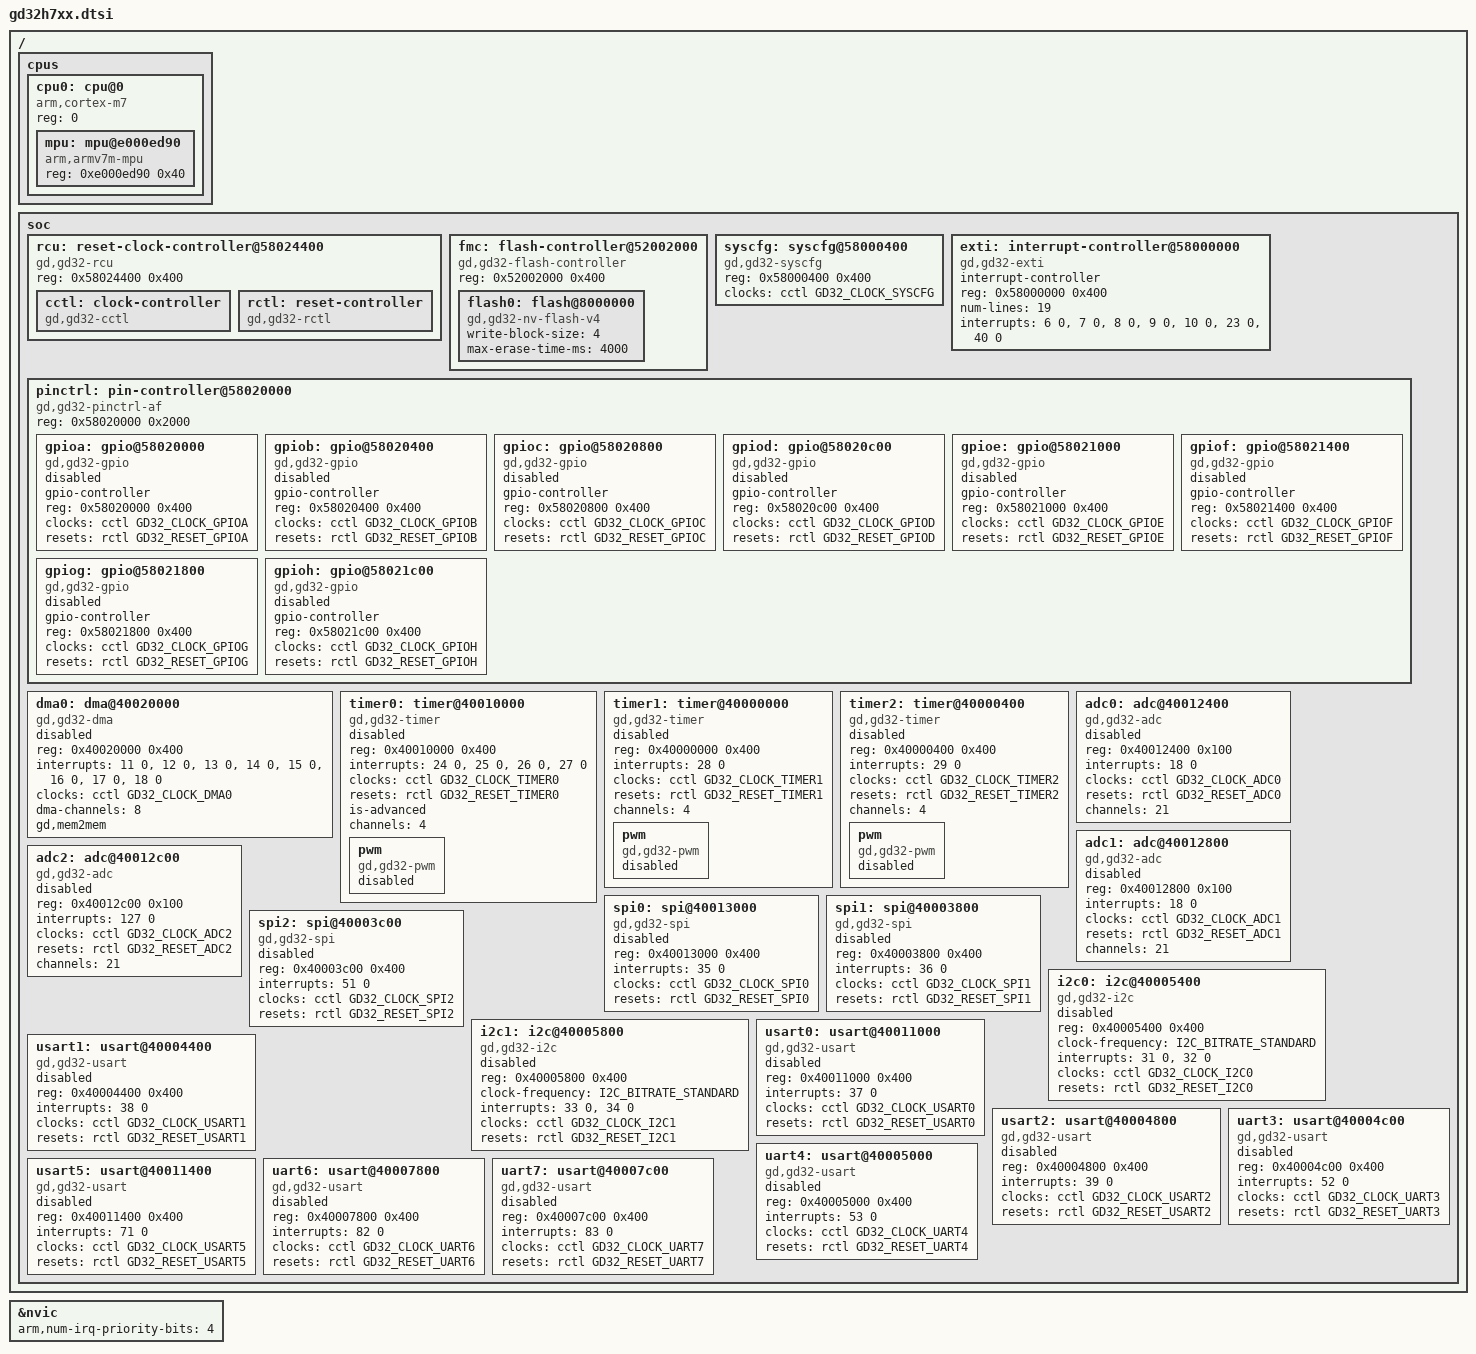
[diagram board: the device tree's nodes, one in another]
/*
 * Copyright (c) 2026 GD32H7xx Zephyr bring-up
 * SPDX-License-Identifier: Apache-2.0
 */

#include <arm/armv7-m.dtsi>
#include <zephyr/dt-bindings/gpio/gpio.h>
#include <zephyr/dt-bindings/i2c/i2c.h>
#include <zephyr/dt-bindings/clock/gd32h7xx-clocks.h>
#include <zephyr/dt-bindings/reset/gd32h7xx.h>

&nvic {
	arm,num-irq-priority-bits = <4>;
};

/ {
	cpus {
		#address-cells = <1>;
		#size-cells = <0>;

		cpu0: cpu@0 {
			compatible = "arm,cortex-m7";
			reg = <0>;
			#address-cells = <1>;
			#size-cells = <1>;

			mpu: mpu@e000ed90 {
				compatible = "arm,armv7m-mpu";
				reg = <0xe000ed90 0x40>;
			};
		};
	};

	soc {
		rcu: reset-clock-controller@58024400 {
			compatible = "gd,gd32-rcu";
			reg = <0x58024400 0x400>;
			status = "okay";

			cctl: clock-controller {
				compatible = "gd,gd32-cctl";
				#clock-cells = <1>;
				status = "okay";
			};

			rctl: reset-controller {
				compatible = "gd,gd32-rctl";
				#reset-cells = <1>;
				status = "okay";
			};
		};

		fmc: flash-controller@52002000 {
			compatible = "gd,gd32-flash-controller";
			reg = <0x52002000 0x400>;

			#address-cells = <1>;
			#size-cells = <1>;

			flash0: flash@8000000 {
				compatible = "gd,gd32-nv-flash-v4", "soc-nv-flash";
				write-block-size = <4>;
				max-erase-time-ms = <4000>;
			};
		};

		syscfg: syscfg@58000400 {
			compatible = "gd,gd32-syscfg";
			reg = <0x58000400 0x400>;
			clocks = <&cctl GD32_CLOCK_SYSCFG>;
			status = "okay";
		};

		exti: interrupt-controller@58000000 {
			compatible = "gd,gd32-exti";
			interrupt-controller;
			#interrupt-cells = <1>;
			reg = <0x58000000 0x400>;
			num-lines = <19>;
			interrupts = <6 0>, <7 0>, <8 0>, <9 0>, <10 0>, <23 0>,
				     <40 0>;
			interrupt-names = "line0", "line1", "line2", "line3",
					  "line4", "line5-9", "line10-15";
			status = "okay";
		};

		pinctrl: pin-controller@58020000 {
			compatible = "gd,gd32-pinctrl-af";
			reg = <0x58020000 0x2000>;
			#address-cells = <1>;
			#size-cells = <1>;
			status = "okay";

			gpioa: gpio@58020000 {
				compatible = "gd,gd32-gpio";
				gpio-controller;
				#gpio-cells = <2>;
				reg = <0x58020000 0x400>;
				clocks = <&cctl GD32_CLOCK_GPIOA>;
				resets = <&rctl GD32_RESET_GPIOA>;
				status = "disabled";
			};

			gpiob: gpio@58020400 {
				compatible = "gd,gd32-gpio";
				gpio-controller;
				#gpio-cells = <2>;
				reg = <0x58020400 0x400>;
				clocks = <&cctl GD32_CLOCK_GPIOB>;
				resets = <&rctl GD32_RESET_GPIOB>;
				status = "disabled";
			};

			gpioc: gpio@58020800 {
				compatible = "gd,gd32-gpio";
				gpio-controller;
				#gpio-cells = <2>;
				reg = <0x58020800 0x400>;
				clocks = <&cctl GD32_CLOCK_GPIOC>;
				resets = <&rctl GD32_RESET_GPIOC>;
				status = "disabled";
			};

			gpiod: gpio@58020c00 {
				compatible = "gd,gd32-gpio";
				gpio-controller;
				#gpio-cells = <2>;
				reg = <0x58020c00 0x400>;
				clocks = <&cctl GD32_CLOCK_GPIOD>;
				resets = <&rctl GD32_RESET_GPIOD>;
				status = "disabled";
			};

			gpioe: gpio@58021000 {
				compatible = "gd,gd32-gpio";
				gpio-controller;
				#gpio-cells = <2>;
				reg = <0x58021000 0x400>;
				clocks = <&cctl GD32_CLOCK_GPIOE>;
				resets = <&rctl GD32_RESET_GPIOE>;
				status = "disabled";
			};

			gpiof: gpio@58021400 {
				compatible = "gd,gd32-gpio";
				gpio-controller;
				#gpio-cells = <2>;
				reg = <0x58021400 0x400>;
				clocks = <&cctl GD32_CLOCK_GPIOF>;
				resets = <&rctl GD32_RESET_GPIOF>;
				status = "disabled";
			};

			gpiog: gpio@58021800 {
				compatible = "gd,gd32-gpio";
				gpio-controller;
				#gpio-cells = <2>;
				reg = <0x58021800 0x400>;
				clocks = <&cctl GD32_CLOCK_GPIOG>;
				resets = <&rctl GD32_RESET_GPIOG>;
				status = "disabled";
			};

			gpioh: gpio@58021c00 {
				compatible = "gd,gd32-gpio";
				gpio-controller;
				#gpio-cells = <2>;
				reg = <0x58021c00 0x400>;
				clocks = <&cctl GD32_CLOCK_GPIOH>;
				resets = <&rctl GD32_RESET_GPIOH>;
				status = "disabled";
			};
		};

		dma0: dma@40020000 {
			compatible = "gd,gd32-dma";
			reg = <0x40020000 0x400>;
			interrupts = <11 0>, <12 0>, <13 0>, <14 0>,
				     <15 0>, <16 0>, <17 0>, <18 0>;
			clocks = <&cctl GD32_CLOCK_DMA0>;
			dma-channels = <8>;
			gd,mem2mem;
			#dma-cells = <2>;
			status = "disabled";
		};

		timer0: timer@40010000 {
			compatible = "gd,gd32-timer";
			reg = <0x40010000 0x400>;
			interrupts = <24 0>, <25 0>, <26 0>, <27 0>;
			interrupt-names = "brk", "up", "trgcom", "cc";
			clocks = <&cctl GD32_CLOCK_TIMER0>;
			resets = <&rctl GD32_RESET_TIMER0>;
			is-advanced;
			channels = <4>;
			status = "disabled";

			pwm {
				compatible = "gd,gd32-pwm";
				status = "disabled";
				#pwm-cells = <3>;
			};
		};

		timer1: timer@40000000 {
			compatible = "gd,gd32-timer";
			reg = <0x40000000 0x400>;
			interrupts = <28 0>;
			interrupt-names = "global";
			clocks = <&cctl GD32_CLOCK_TIMER1>;
			resets = <&rctl GD32_RESET_TIMER1>;
			channels = <4>;
			status = "disabled";

			pwm {
				compatible = "gd,gd32-pwm";
				status = "disabled";
				#pwm-cells = <3>;
			};
		};

		timer2: timer@40000400 {
			compatible = "gd,gd32-timer";
			reg = <0x40000400 0x400>;
			interrupts = <29 0>;
			interrupt-names = "global";
			clocks = <&cctl GD32_CLOCK_TIMER2>;
			resets = <&rctl GD32_RESET_TIMER2>;
			channels = <4>;
			status = "disabled";

			pwm {
				compatible = "gd,gd32-pwm";
				status = "disabled";
				#pwm-cells = <3>;
			};
		};

		adc0: adc@40012400 {
			compatible = "gd,gd32-adc";
			reg = <0x40012400 0x100>;
			interrupts = <18 0>;
			clocks = <&cctl GD32_CLOCK_ADC0>;
			resets = <&rctl GD32_RESET_ADC0>;
			channels = <21>;
			status = "disabled";
			#io-channel-cells = <1>;
		};

		adc1: adc@40012800 {
			compatible = "gd,gd32-adc";
			reg = <0x40012800 0x100>;
			interrupts = <18 0>;
			clocks = <&cctl GD32_CLOCK_ADC1>;
			resets = <&rctl GD32_RESET_ADC1>;
			channels = <21>;
			status = "disabled";
			#io-channel-cells = <1>;
		};

		adc2: adc@40012c00 {
			compatible = "gd,gd32-adc";
			reg = <0x40012c00 0x100>;
			interrupts = <127 0>;
			clocks = <&cctl GD32_CLOCK_ADC2>;
			resets = <&rctl GD32_RESET_ADC2>;
			channels = <21>;
			status = "disabled";
			#io-channel-cells = <1>;
		};

		spi0: spi@40013000 {
			compatible = "gd,gd32-spi";
			reg = <0x40013000 0x400>;
			interrupts = <35 0>;
			clocks = <&cctl GD32_CLOCK_SPI0>;
			resets = <&rctl GD32_RESET_SPI0>;
			status = "disabled";
		};

		spi1: spi@40003800 {
			compatible = "gd,gd32-spi";
			reg = <0x40003800 0x400>;
			interrupts = <36 0>;
			clocks = <&cctl GD32_CLOCK_SPI1>;
			resets = <&rctl GD32_RESET_SPI1>;
			status = "disabled";
		};

		spi2: spi@40003c00 {
			compatible = "gd,gd32-spi";
			reg = <0x40003c00 0x400>;
			interrupts = <51 0>;
			clocks = <&cctl GD32_CLOCK_SPI2>;
			resets = <&rctl GD32_RESET_SPI2>;
			status = "disabled";
		};

		i2c0: i2c@40005400 {
			compatible = "gd,gd32-i2c";
			reg = <0x40005400 0x400>;
			#address-cells = <1>;
			#size-cells = <0>;
			clock-frequency = <I2C_BITRATE_STANDARD>;
			interrupts = <31 0>, <32 0>;
			interrupt-names = "event", "error";
			clocks = <&cctl GD32_CLOCK_I2C0>;
			resets = <&rctl GD32_RESET_I2C0>;
			status = "disabled";
		};

		i2c1: i2c@40005800 {
			compatible = "gd,gd32-i2c";
			reg = <0x40005800 0x400>;
			#address-cells = <1>;
			#size-cells = <0>;
			clock-frequency = <I2C_BITRATE_STANDARD>;
			interrupts = <33 0>, <34 0>;
			interrupt-names = "event", "error";
			clocks = <&cctl GD32_CLOCK_I2C1>;
			resets = <&rctl GD32_RESET_I2C1>;
			status = "disabled";
		};

		usart0: usart@40011000 {
			compatible = "gd,gd32-usart";
			reg = <0x40011000 0x400>;
			interrupts = <37 0>;
			clocks = <&cctl GD32_CLOCK_USART0>;
			resets = <&rctl GD32_RESET_USART0>;
			status = "disabled";
		};

		usart1: usart@40004400 {
			compatible = "gd,gd32-usart";
			reg = <0x40004400 0x400>;
			interrupts = <38 0>;
			clocks = <&cctl GD32_CLOCK_USART1>;
			resets = <&rctl GD32_RESET_USART1>;
			status = "disabled";
		};

		usart2: usart@40004800 {
			compatible = "gd,gd32-usart";
			reg = <0x40004800 0x400>;
			interrupts = <39 0>;
			clocks = <&cctl GD32_CLOCK_USART2>;
			resets = <&rctl GD32_RESET_USART2>;
			status = "disabled";
		};

		uart3: usart@40004c00 {
			compatible = "gd,gd32-usart";
			reg = <0x40004c00 0x400>;
			interrupts = <52 0>;
			clocks = <&cctl GD32_CLOCK_UART3>;
			resets = <&rctl GD32_RESET_UART3>;
			status = "disabled";
		};

		uart4: usart@40005000 {
			compatible = "gd,gd32-usart";
			reg = <0x40005000 0x400>;
			interrupts = <53 0>;
			clocks = <&cctl GD32_CLOCK_UART4>;
			resets = <&rctl GD32_RESET_UART4>;
			status = "disabled";
		};

		usart5: usart@40011400 {
			compatible = "gd,gd32-usart";
			reg = <0x40011400 0x400>;
			interrupts = <71 0>;
			clocks = <&cctl GD32_CLOCK_USART5>;
			resets = <&rctl GD32_RESET_USART5>;
			status = "disabled";
		};

		uart6: usart@40007800 {
			compatible = "gd,gd32-usart";
			reg = <0x40007800 0x400>;
			interrupts = <82 0>;
			clocks = <&cctl GD32_CLOCK_UART6>;
			resets = <&rctl GD32_RESET_UART6>;
			status = "disabled";
		};

		uart7: usart@40007c00 {
			compatible = "gd,gd32-usart";
			reg = <0x40007c00 0x400>;
			interrupts = <83 0>;
			clocks = <&cctl GD32_CLOCK_UART7>;
			resets = <&rctl GD32_RESET_UART7>;
			status = "disabled";
		};
	};
};
